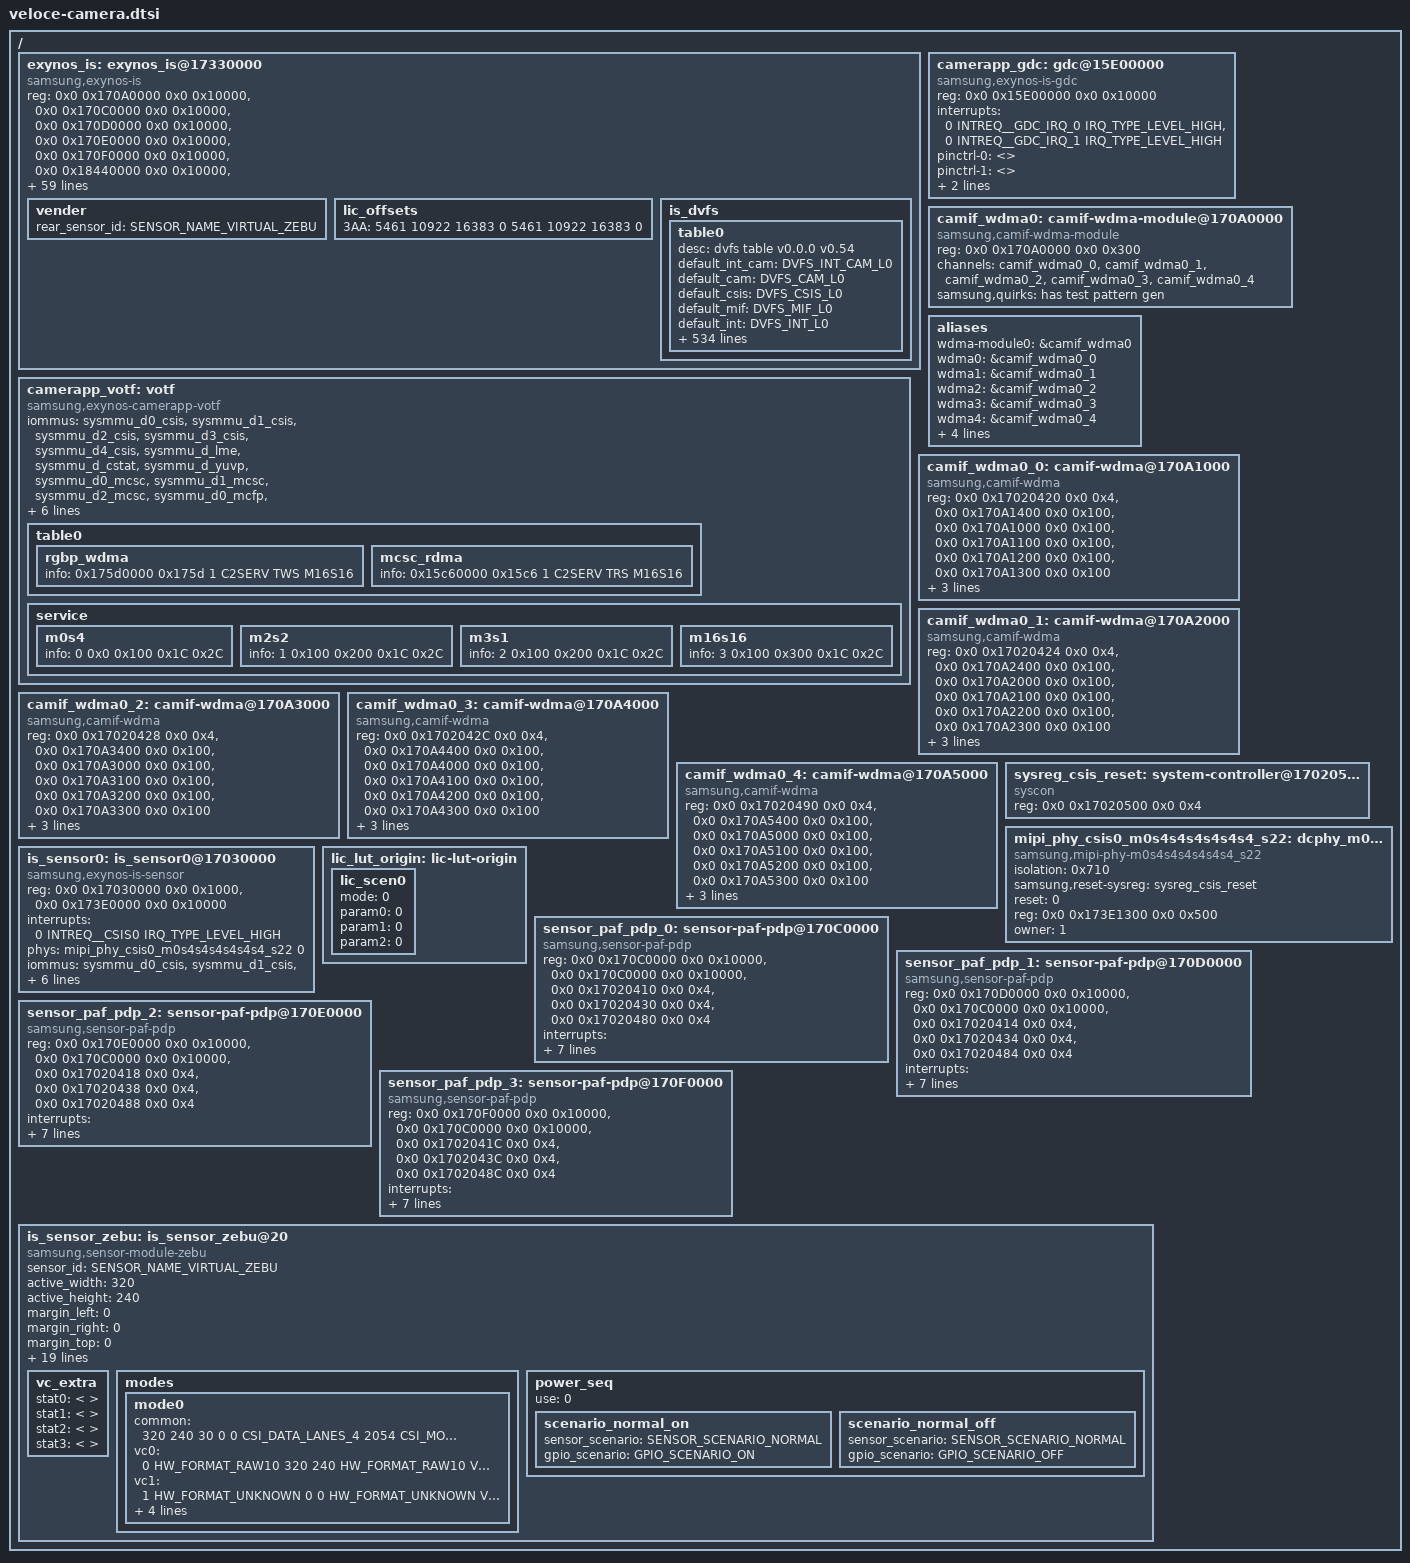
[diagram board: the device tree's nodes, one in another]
/*
 * SAMSUNG EXYNOS9925 SoC camera device tree source
 *
 * Copyright (c) 2020 Samsung Electronics Co., Ltd.
 *		http://www.samsung.com
 *
 * SAMSUNG EXYNOS9925 SoC camera device nodes are listed in this file.
 * EXYNOS9925 based board files can include this file and provide
 * values for board specfic bindings.
 *
 * This program is free software; you can redistribute it and/or modify
 * it under the terms of the GNU General Public License version 2 as
 * published by the Free Software Foundation.
 */

//#include <dt-bindings/clock/exynos9925.h>
#include <dt-bindings/interrupt-controller/arm-gic.h>
#include <dt-bindings/interrupt-controller/exynos9925.h>
#include <dt-bindings/soc/samsung,sysmmu-v8.h>
#include <dt-bindings/camera/exynos_is_dt.h>
#include <dt-bindings/camera/votf.h>
//#include "EXYNOS9925-pinctrl.dtsi"

/ {
	exynos_is: exynos_is@17330000 {
		compatible = "samsung,exynos-is";
		reg = <0x0 0x170A0000 0x0 0x10000>, /* CSIS_WDMA */
			<0x0 0x170C0000 0x0 0x10000>, /* PDP_CORE0 */
			<0x0 0x170D0000 0x0 0x10000>, /* PDP_CORE1 */
			<0x0 0x170E0000 0x0 0x10000>, /* PDP_CORE2 */
			<0x0 0x170F0000 0x0 0x10000>, /* PDP_CORE3 */
			<0x0 0x18440000 0x0 0x10000>, /* CSTAT0 */
			<0x0 0x18450000 0x0 0x20000>, /* CSTAT1 */
			<0x0 0x18460000 0x0 0x30000>, /* CSTAT2 */
			<0x0 0x18470000 0x0 0x40000>, /* CSTAT3 */
			<0x0 0x170A0000 0x0 0x10000>, /* ZSL/STRIP DMA  */
			<0x0 0x17730000 0x0 0x10000>, /* LME */
			<0x0 0x15F80000 0x0 0x10000>, /* BYRP */
			<0x0 0x175B0000 0x0 0x10000>, /* RGBP */
			<0x0 0x17430000 0x0 0x10000>, /* DRCP */
			<0x0 0x17B00000 0x0 0x10000>, /* MCFP */
			<0x0 0x18080000 0x0 0x10000>, /* YUVP */
			<0x0 0x15C40000 0x0 0x10000>; /* MCSC */
		interrupts = <0 INTREQ__CSTAT_CH0_0 IRQ_TYPE_LEVEL_HIGH>, /*CSTAT0_0 */
			<0 INTREQ__CSTAT_CH0_1 IRQ_TYPE_LEVEL_HIGH>,      /* CSTAT0_1 */
			<0 INTREQ__CSTAT_CH1_0 IRQ_TYPE_LEVEL_HIGH>,      /* CSTAT1_0 */
			<0 INTREQ__CSTAT_CH1_1 IRQ_TYPE_LEVEL_HIGH>,      /* CSTAT1_1 */
			<0 INTREQ__CSTAT_CH2_0 IRQ_TYPE_LEVEL_HIGH>,      /* CSTAT2_0 */
			<0 INTREQ__CSTAT_CH2_1 IRQ_TYPE_LEVEL_HIGH>,      /* CSTAT2_1 */
			<0 INTREQ__CSTAT_CH3_0 IRQ_TYPE_LEVEL_HIGH>,      /* CSTAT3_0 */
			<0 INTREQ__CSTAT_CH3_1 IRQ_TYPE_LEVEL_HIGH>,      /* CSTAT3_1 */
			<0 INTREQ__LME_O_INT0 IRQ_TYPE_LEVEL_HIGH>,       /* LME_0 */
			<0 INTREQ__BYRP_0 IRQ_TYPE_LEVEL_HIGH>,           /* BYRP_0 */
			<0 INTREQ__BYRP_1 IRQ_TYPE_LEVEL_HIGH>,           /* BYRP_1 */
			<0 INTREQ__RGBP_0 IRQ_TYPE_LEVEL_HIGH>,           /* RGBP_0 */
			<0 INTREQ__RGBP_1 IRQ_TYPE_LEVEL_HIGH>,           /* RGBP_1 */
			<0 INTREQ__MCFP_0 IRQ_TYPE_LEVEL_HIGH>,           /* MCFP_0 */
			<0 INTREQ__MCFP_1 IRQ_TYPE_LEVEL_HIGH>,           /* MCFP_1 */
			<0 INTREQ__YUVP_0 IRQ_TYPE_LEVEL_HIGH>,           /* YUVP_0 */
			<0 INTREQ__YUVP_1 IRQ_TYPE_LEVEL_HIGH>,           /* YUVP_1 */
			<0 INTREQ__DRCP_0 IRQ_TYPE_LEVEL_HIGH>,           /* DRCP_0 */
			<0 INTREQ__DRCP_1 IRQ_TYPE_LEVEL_HIGH>,           /* DRCP_1 */
			<0 INTREQ__MCSC_INTREQ_0 IRQ_TYPE_LEVEL_HIGH>,    /* MCSC_0 */
			<0 INTREQ__MCSC_INTREQ_1 IRQ_TYPE_LEVEL_HIGH>;    /* MCSC_1 */
		pinctrl-names = "default","release";
		pinctrl-0 = <>;
		pinctrl-1 = <>;

		status = "ok";
		iommus = <&sysmmu_d0_csis>,
			<&sysmmu_d1_csis>,
			<&sysmmu_d2_csis>,
			<&sysmmu_d3_csis>,
			<&sysmmu_d4_csis>,
			<&sysmmu_d_lme>,
			<&sysmmu_d_cstat>,
			<&sysmmu_d_yuvp>,
			<&sysmmu_d0_mcsc>,
			<&sysmmu_d1_mcsc>,
			<&sysmmu_d2_mcsc>,
			<&sysmmu_d0_mcfp>,
			<&sysmmu_d1_mcfp>,
			<&sysmmu_d2_mcfp>,
			<&sysmmu_d3_mcfp>,
			<&sysmmu_d4_mcfp>,
			<&sysmmu_d5_mcfp>,
			<&sysmmu_d0_rgbp>,
			<&sysmmu_d1_rgbp>,
			<&sysmmu_d_drcp>,
			<&sysmmu_d_byrp>;
		samsung,iommu-group = <&iommu_group_is>;
		#cooling-cells = <2>; /* min followed by max */
		/* ewf-index = <EWF_CMU_BUSC>; */
		list-scen-bts = "camera_default";
		num_of_3aa = <4>;
		num_of_lme = <1>;
		num_of_isp = <0>;
		num_of_byrp = <1>;
		num_of_rgbp = <1>;
		num_of_mcsc = <1>;
		num_of_vra = <0>;
		num_of_clh = <0>;
		num_of_ypp = <1>;
		num_of_mcfp = <1>;

		memory-region = <&camera_rmem>;
		samsung,tzmp;
	};

	camerapp_gdc: gdc@15E00000 {
		compatible = "samsung,exynos-is-gdc";
		reg = <0x0 0x15E00000 0x0 0x10000>; /* GDC */
		interrupts = <0 INTREQ__GDC_IRQ_0 IRQ_TYPE_LEVEL_HIGH>, /* GDC_0 */
			<0 INTREQ__GDC_IRQ_1 IRQ_TYPE_LEVEL_HIGH>;    /* GDC_1 */
		pinctrl-names = "default","release";
		pinctrl-0 = <>;
		pinctrl-1 = <>;

		status = "okay";
		iommus = <&sysmmu_d0_mcsc>;
		samsung,iommu-group = <&iommu_group_is>;
		#cooling-cells = <2>; /* min followed by max */
	};

	camerapp_votf: votf {
		compatible = "samsung,exynos-camerapp-votf";
		iommus = <&sysmmu_d0_csis>,
			<&sysmmu_d1_csis>,
			<&sysmmu_d2_csis>,
			<&sysmmu_d3_csis>,
			<&sysmmu_d4_csis>,
			<&sysmmu_d_lme>,
			<&sysmmu_d_cstat>,
			<&sysmmu_d_yuvp>,
			<&sysmmu_d0_mcsc>,
			<&sysmmu_d1_mcsc>,
			<&sysmmu_d2_mcsc>,
			<&sysmmu_d0_mcfp>,
			<&sysmmu_d1_mcfp>,
			<&sysmmu_d2_mcfp>,
			<&sysmmu_d3_mcfp>,
			<&sysmmu_d4_mcfp>,
			<&sysmmu_d5_mcfp>,
			<&sysmmu_d0_rgbp>,
			<&sysmmu_d1_rgbp>,
			<&sysmmu_d_drcp>,
			<&sysmmu_d_byrp>;
		samsung,iommu-group = <&iommu_group_is>;
		status = "okay";
		use_axi;

		table0{
			/* base address, ip num, id cnt, C2SERV/C2AGENT, TWS/TRS, module type */
			/*
			csis_wdma0 { info = <0x17380000 0x1738 16 C2SERV TWS M16S16>; };
			csis_wdma1 { info = <0x17390000 0x1739 4 C2SERV TWS M16S16>; };
			pdp_rdma   { info = <0x173a0000 0x173a 4 C2SERV TRS M16S16>; };
			byrp_wdma  { info = <0x15fa0000 0x15fa 2 C2SERV TWS M16S16>; };
			byrp_rdma  { info = <0x15fc0000 0x15fc 1 C2SERV TRS M16S16>; };
			cstat_wdma0 { info = <0x18510000 0x1851 16 C2SERV TWS M16S16>; };
			cstat_wdma1 { info = <0x18520000 0x1852 16 C2SERV TWS M16S16>; };
			cstat_wdma2 { info = <0x18530000 0x1853 4 C2SERV TWS M16S16>; };
			cstat_rdma { info = <0x18500000 0x1850 4 C2SERV TRS M16S16>; };
			rgbp_rdma { info = <0x175c0000 0x175c 4 C2SERV TWS M16S16>; };
			*/
			rgbp_wdma { info = <0x175d0000 0x175d 1 C2SERV TWS M16S16>; };
			mcsc_rdma  { info = <0x15c60000 0x15c6 1 C2SERV TRS M16S16>; };
			/*
			mcsc_wdma  { info = <0x16c50000 0x15c5 16 C2SERV TWS M16S16>; };
			gdc_rdma   { info = <0x15e20000 0x15e2 2 C2SERV TRS M16S16>; };
			gdc_wdma   { info = <0x15e10000 0x15e1 1 C2SERV TWS M16S16>; };
			lme_rdma   { info = <0x17740000 0x1774 16 C2SERV TRS M16S16>; };
			*/
		};

		service {
			/* num, tws addr, trs addr, tws gap, trs gap */
			m0s4 { info = <0 0x0 0x100 0x1C 0x2C>; };
			m2s2 { info = <1 0x100 0x200 0x1C 0x2C>; };
			m3s1 { info = <2 0x100 0x200 0x1C 0x2C>; };
			m16s16 { info = <3 0x100 0x300 0x1C 0x2C>; };
		};
	};

	camif_wdma0: camif-wdma-module@170A0000 {
		compatible = "samsung,camif-wdma-module";
		reg = <0x0 0x170A0000 0x0 0x300>;
		reg-names = "ctl";
		channels = <&camif_wdma0_0>,
			<&camif_wdma0_1>,
			<&camif_wdma0_2>,
			<&camif_wdma0_3>,
			<&camif_wdma0_4>;
		samsung,quirks = "has test pattern gen";
	};

	aliases {
		wdma-module0 = &camif_wdma0;
	};

	camif_wdma0_0: camif-wdma@170A1000 {
		compatible = "samsung,camif-wdma";
		reg = <0x0 0x17020420 0x0 0x4>,	/* input MUX */
			<0x0 0x170A1400 0x0 0x100>,	/* CTL */
			<0x0 0x170A1000 0x0 0x100>,	/* VC0 */
			<0x0 0x170A1100 0x0 0x100>,	/* VC1 */
			<0x0 0x170A1200 0x0 0x100>,	/* VC2 */
			<0x0 0x170A1300 0x0 0x100>;	/* VC3 */
		reg-names = "mux", "ctl", "vc0", "vc1", "vc2", "vc3";
		interrupts = <GIC_SPI INTREQ__CSIS_DMA0 IRQ_TYPE_LEVEL_HIGH>;
		interrupt-names = "dma";
		module = <&camif_wdma0>;
	};

	camif_wdma0_1: camif-wdma@170A2000 {
		compatible = "samsung,camif-wdma";
		reg = <0x0 0x17020424 0x0 0x4>,	/* input MUX */
			<0x0 0x170A2400 0x0 0x100>,	/* CTL */
			<0x0 0x170A2000 0x0 0x100>,	/* VC0 */
			<0x0 0x170A2100 0x0 0x100>,	/* VC1 */
			<0x0 0x170A2200 0x0 0x100>,	/* VC2 */
			<0x0 0x170A2300 0x0 0x100>;	/* VC3 */
		reg-names = "mux", "ctl", "vc0", "vc1", "vc2", "vc3";
		interrupts = <GIC_SPI INTREQ__CSIS_DMA1 IRQ_TYPE_LEVEL_HIGH>;
		interrupt-names = "dma";
		module = <&camif_wdma0>;
	};

	camif_wdma0_2: camif-wdma@170A3000 {
		compatible = "samsung,camif-wdma";
		reg = <0x0 0x17020428 0x0 0x4>,	/* input MUX */
			<0x0 0x170A3400 0x0 0x100>,	/* CTL */
			<0x0 0x170A3000 0x0 0x100>,	/* VC0 */
			<0x0 0x170A3100 0x0 0x100>,	/* VC1 */
			<0x0 0x170A3200 0x0 0x100>,	/* VC2 */
			<0x0 0x170A3300 0x0 0x100>;	/* VC3 */
		reg-names = "mux", "ctl", "vc0", "vc1", "vc2", "vc3";
		interrupts = <GIC_SPI INTREQ__CSIS_DMA2 IRQ_TYPE_LEVEL_HIGH>;
		interrupt-names = "dma";
		module = <&camif_wdma0>;
	};

	camif_wdma0_3: camif-wdma@170A4000 {
		compatible = "samsung,camif-wdma";
		reg = <0x0 0x1702042C 0x0 0x4>,	/* input MUX */
			<0x0 0x170A4400 0x0 0x100>,	/* CTL */
			<0x0 0x170A4000 0x0 0x100>,	/* VC0 */
			<0x0 0x170A4100 0x0 0x100>,	/* VC1 */
			<0x0 0x170A4200 0x0 0x100>,	/* VC2 */
			<0x0 0x170A4300 0x0 0x100>;	/* VC3 */
		reg-names = "mux", "ctl", "vc0", "vc1", "vc2", "vc3";
		interrupts = <GIC_SPI INTREQ__CSIS_DMA3 IRQ_TYPE_LEVEL_HIGH>;
		interrupt-names = "dma";
		module = <&camif_wdma0>;
	};

	camif_wdma0_4: camif-wdma@170A5000 {
		compatible = "samsung,camif-wdma";
		reg = <0x0 0x17020490 0x0 0x4>,	/* input MUX */
			<0x0 0x170A5400 0x0 0x100>,	/* CTL */
			<0x0 0x170A5000 0x0 0x100>,	/* VC0 */
			<0x0 0x170A5100 0x0 0x100>,	/* VC1 */
			<0x0 0x170A5200 0x0 0x100>,	/* VC2 */
			<0x0 0x170A5300 0x0 0x100>;	/* VC3 */
		reg-names = "mux", "ctl", "vc0", "vc1", "vc2", "vc3";
		interrupts = <GIC_SPI INTREQ__CSIS_DMA4 IRQ_TYPE_LEVEL_HIGH>;
		interrupt-names = "dma";
		module = <&camif_wdma0>;
	};

	aliases {
		wdma0 = &camif_wdma0_0;
		wdma1 = &camif_wdma0_1;
		wdma2 = &camif_wdma0_2;
		wdma3 = &camif_wdma0_3;
		wdma4 = &camif_wdma0_4;
	};

	sysreg_csis_reset: system-controller@17020500 {
		compatible = "syscon";
		reg = <0x0 0x17020500 0x0 0x4>;
	};

	mipi_phy_csis0_m0s4s4s4s4s4s4_s22: dcphy_m0s4s4s4s4s4s4_s22_csi0@173E1300 {
		/* DPHY 6.5Gbps 4-lane, CPHY 6.0 Gsps 3-trio */
		compatible = "samsung,mipi-phy-m0s4s4s4s4s4s4_s22";

		//samsung,pmu-syscon = <&pmu_system_controller>;
		isolation = <0x710>; /* PMU address offset */

		samsung,reset-sysreg = <&sysreg_csis_reset>;
		reset = <0>; /* reset bit */

		reg = <0x0 0x173E1300 0x0 0x500>;
		owner = <1>; /* 0: DSI, 1: CSI */
		#phy-cells = <1>;
	};

	is_sensor0: is_sensor0@17030000 {
		/* CSIS0 */
		compatible = "samsung,exynos-is-sensor";
		#address-cells = <1>;
		#size-cells = <1>;
		reg = <0x0 0x17030000 0x0 0x1000>, /* MIPI-CSI0 */
			<0x0 0x173E0000 0x0 0x10000>; /* PHY: M0S4S4S4S4S4S4_S22 */
		reg-names = "csi", "phy";
		interrupts = <0 INTREQ__CSIS0 IRQ_TYPE_LEVEL_HIGH>; /* MIPI-CSI0 */
		interrupt-names = "csi";
		phys = <&mipi_phy_csis0_m0s4s4s4s4s4s4_s22 0>;
		phy-names = "csis_dphy";
		iommus = <&sysmmu_d0_csis>,
		       <&sysmmu_d1_csis>,
		       <&sysmmu_d2_csis>,
		       <&sysmmu_d3_csis>,
		       <&sysmmu_d4_csis>;
		samsung,iommu-group = <&iommu_group_is>;
	};

	lic_lut_origin: lic-lut-origin {
		#define LIC_MODE_DYNAMIC	(0)
		#define LIC_MODE_STATIC		(1)
		#define LIC_PATH_OTF		(0)
		#define LIC_PATH_DMA		(1)
		/*
		 * When DYNAMIC mode is selected, param means enable limitation for DMA path.
		 * Example:
		 * @ mode = <LIC_MODE_DYNAMIC>;
		 * @ param0 = <LIC_PATH_OTF>;
		 * @ param1 = <LIC_PATH_DMA>;
		 * @ param2 = <LIC_PATH_OTF>;
		 *
		 * When STATIC mode is selected, param means buffer size for each context.
		 * Example:
		 * @ mode = <LIC_MODE_STAIC>;
		 * @ param0 = <3584>;
		 * @ param1 = <3583>;
		 * @ param2 = <1>;
		 *
		 * The lic_scen0 is not abailable. If the index of LUT is "0", the selection is skipped.
		 */
		lic_scen0 { /* Reserved */
			mode = <0>;
			param0 = <0>;
			param1 = <0>;
			param2 = <0>;
		};
	};

	sensor_paf_pdp_0: sensor-paf-pdp@170C0000 {
		compatible = "samsung,sensor-paf-pdp";
		reg = <0x0 0x170C0000 0x0 0x10000>, /* PDP CORE0 */
			<0x0 0x170C0000 0x0 0x10000>, /* PDP CORE0: For common regiser */
			<0x0 0x17020410 0x0 0x4>, /* CSIS_PDP_SC_CON0: PDP0 input mux */
			<0x0 0x17020430 0x0 0x4>, /* PDP_VC_CON0: PDP0 VC input mux */
			<0x0 0x17020480 0x0 0x4>; /* CSIS_PDP_SC_PDP0_IN_EN: PDP0 input enable */
		reg-names = "core", "common", "mux", "vc_mux", "en";
		interrupts = <0 INTREQ__PDP0 IRQ_TYPE_LEVEL_HIGH>,
			<0 INTREQ__PDP1 IRQ_TYPE_LEVEL_HIGH>;
		mux = <0 1 2 3 4 5>; /* <csi0 csi1 csi2 csi3 csi4 csi5> */
		vc_mux = <0x1 0x1 0x1 0x1 0x1 0x1 0x1>; /* <csi0 csi1 csi2 csi3 csi4 csi5 csi6> */
		en = <0 1 2 3 4 5 6>; /* bit postion: <csi0 csi1 csi2 csi3 csi4 csi5 csi6> */
		leader; /* have RDMA & create video node */
		lic_lut = <&lic_lut_origin>;
		//clocks = <&clock GATE_PDP_TOP_QCH_PDP_TOP>;
		//clock-names = "aclk";

	};

	sensor_paf_pdp_1: sensor-paf-pdp@170D0000 {
		compatible = "samsung,sensor-paf-pdp";
		reg = <0x0 0x170D0000 0x0 0x10000>, /* PDP CORE1 */
			<0x0 0x170C0000 0x0 0x10000>, /* PDP CORE0: For common regiser */
			<0x0 0x17020414 0x0 0x4>, /* CSIS_PDP_SC_CON1: PDP1 input mux */
			<0x0 0x17020434 0x0 0x4>, /* PDP_VC_CON1: PDP1 VC input mux */
			<0x0 0x17020484 0x0 0x4>; /* CSIS_PDP_SC_PDP1_IN_EN: PDP1 input enable */
		reg-names = "core", "common", "mux", "vc_mux", "en";
		interrupts = <0 INTREQ__PDP2 IRQ_TYPE_LEVEL_HIGH>,
			<0 INTREQ__PDP3 IRQ_TYPE_LEVEL_HIGH>;
		mux = <0 1 2 3 4 5>; /* <csi0 csi1 csi2 csi3 csi4 csi5> */
		vc_mux = <0x1 0x1 0x1 0x1 0x1 0x1 0x1>; /* <csi0 csi1 csi2 csi3 csi4 csi5 csi6> */
		en = <0 1 2 3 4 5 6>; /* bit postion: <csi0 csi1 csi2 csi3 csi4 csi5 csi6> */
		leader; /* have RDMA & create video node */
		lic_lut = <&lic_lut_origin>;
		//clocks = <&clock GATE_PDP_TOP_QCH_PDP_TOP>;
		//clock-names = "aclk";

	};

	sensor_paf_pdp_2: sensor-paf-pdp@170E0000 {
		compatible = "samsung,sensor-paf-pdp";
		reg = <0x0 0x170E0000 0x0 0x10000>, /* PDP CORE2 */
			<0x0 0x170C0000 0x0 0x10000>, /* PDP CORE0: For common regiser */
			<0x0 0x17020418 0x0 0x4>, /* CSIS_PDP_SC_CON2: PDP2 input mux */
			<0x0 0x17020438 0x0 0x4>, /* PDP_VC_CON2: PDP2 VC input mux */
			<0x0 0x17020488 0x0 0x4>; /* CSIS_PDP_SC_PDP2_IN_EN: PDP2 input enable */
		reg-names = "core", "common", "mux", "vc_mux", "en";
		interrupts = <0 INTREQ__PDP4 IRQ_TYPE_LEVEL_HIGH>,
			<0 INTREQ__PDP5 IRQ_TYPE_LEVEL_HIGH>;
		mux = <0 1 2 3 4 5>; /* <csi0 csi1 csi2 csi3 csi4 csi5> */
		vc_mux = <0x1 0x1 0x1 0x1 0x1 0x1 0x1>; /* <csi0 csi1 csi2 csi3 csi4 csi5 csi6> */
		en = <0 1 2 3 4 5 6>; /* bit postion: <csi0 csi1 csi2 csi3 csi4 csi5 csi6> */
		leader; /* have RDMA & create video node */
		lic_lut = <&lic_lut_origin>;
		//clocks = <&clock GATE_PDP_TOP_QCH_PDP_TOP>;
		//clock-names = "aclk";

	};

	sensor_paf_pdp_3: sensor-paf-pdp@170F0000 {
		compatible = "samsung,sensor-paf-pdp";
		reg = <0x0 0x170F0000 0x0 0x10000>, /* PDP CORE3 */
			<0x0 0x170C0000 0x0 0x10000>, /* PDP CORE0: For common regiser */
			<0x0 0x1702041C 0x0 0x4>, /* CSIS_PDP_SC_CON3: PDP3 input mux */
			<0x0 0x1702043C 0x0 0x4>, /* PDP_VC_CON3: PDP3 VC input mux */
			<0x0 0x1702048C 0x0 0x4>; /* CSIS_PDP_SC_PDP3_IN_EN: PDP3 input enable */
		reg-names = "core", "common", "mux", "vc_mux", "en";
		interrupts = <0 INTREQ__PDP6 IRQ_TYPE_LEVEL_HIGH>,
			<0 INTREQ__PDP7 IRQ_TYPE_LEVEL_HIGH>;
		mux = <0 1 2 3 4 5>; /* <csi0 csi1 csi2 csi3 csi4 csi5> */
		vc_mux = <0x1 0x1 0x1 0x1 0x1 0x1 0x1>; /* <csi0 csi1 csi2 csi3 csi4 csi5 csi6> */
		en = <0 1 2 3 4 5 6>; /* bit postion: <csi0 csi1 csi2 csi3 csi4 csi5 csi6> */
		leader; /* have RDMA & create video node */
		lic_lut = <&lic_lut_origin>;
		//clocks = <&clock GATE_PDP_TOP_QCH_PDP_TOP>;
		//clock-names = "aclk";

	};

	aliases {
		pdp0 = &sensor_paf_pdp_0;
		pdp1 = &sensor_paf_pdp_1;
		pdp2 = &sensor_paf_pdp_2;
		pdp3 = &sensor_paf_pdp_3;
	};

	is_sensor_zebu: is_sensor_zebu@20 {
		compatible = "samsung,sensor-module-zebu";
		/* common */
		sensor_id = <SENSOR_NAME_VIRTUAL_ZEBU>;
		active_width = <320>;
		active_height = <240>;
		margin_left = <0>;
		margin_right = <0>;
		margin_top = <0>;
		margin_bottom = <0>;
		max_framerate = <30>;
		bitwidth = <10>;
		use_retention_mode = <SENSOR_RETENTION_INACTIVE>;
		sensor_maker = "SLSI";
		sensor_name = "ZEBU";
		setfile_name = "setfile_rear.bin";

		pinctrl-names = "pin0", "pin1", "pin2", "release";
		pinctrl-0 = <>;
		pinctrl-1 = <>;
		pinctrl-2 = <>;
		pinctrl-3 = <>;

		use_img_drv = <1>;
		reg = <0x0 0x0FC00000 0x0 0x10000>; /* IMG_DRV */
		rmem = <&img_drv_rmem>;
		bin_path = "/data/";

		/* board */
		position = <0>;	/* Rear:0. Front:1. Rear_sub:2. Secure:3. */
		id = <0>; /* is_sensor id */
		mclk_ch = <0>;
		sensor_i2c_ch = <0>; /* SENSOR_CONTROL_I2C0 */

		status = "okay";

		vc_extra {
			/* ex) statX = <stat_type, sensor_mode, max_width, max_height, max_element> */
			stat0 = </* not avaliable */>;	/* VC_BUF_DATA_TYPE_SENSOR_STAT1 */
			stat1 = </* not available */>;	/* VC_BUF_DATA_TYPE_GENERAL_STAT1 */
			stat2 = </* not avaliable */>;	/* VC_BUF_DATA_TYPE_SENSOR_STAT2 */
			stat3 = </* not available */>;	/* VC_BUF_DATA_TYPE_GENERAL_STAT2 */
		};

		/* sensor modes */
		modes {
				/* common = <width, height, fps, settle, mode, lane, speed, interleave, lrte, pd_mode> */
				/* vcX = <map, hwformat, width, height, hwformat, type, width, height> */
			mode0 {
				common = <320 240 30 0 0 CSI_DATA_LANES_4 2054 CSI_MODE_VC_DT LRTE_DISABLE PD_NONE EX_NONE>;
				vc0 = </* in */ 0 HW_FORMAT_RAW10 320 240	/* out */ HW_FORMAT_RAW10 VC_NOTHING 320 240>;
				vc1 = </* in */ 1 HW_FORMAT_UNKNOWN 0 0		/* out */ HW_FORMAT_UNKNOWN VC_NOTHING 0 0>;
				vc2 = </* in */ 2 HW_FORMAT_UNKNOWN 0 0		/* out */ HW_FORMAT_UNKNOWN VC_NOTHING 0 0>;
				vc3 = </* in */ 3 HW_FORMAT_UNKNOWN 0 0		/* out */ HW_FORMAT_UNKNOWN VC_NOTHING 0 0>;
			};
		};

		power_seq {
			use = <0>;
			scenario_normal_on {
				sensor_scenario = <SENSOR_SCENARIO_NORMAL>;
				gpio_scenario = <GPIO_SCENARIO_ON>;

				/* A start node number should be over the 10 for reserved number 0~9. */
				/* pname = "name"; pin = <act value dealy voltage>; gpio = <gpx# # 0x1>; */
			};

			scenario_normal_off {
				sensor_scenario = <SENSOR_SCENARIO_NORMAL>;
				gpio_scenario = <GPIO_SCENARIO_OFF>;

				/* A start node number should be over the 10 for reserved number 0~9. */
				/* pname = "name"; pin = <act value dealy voltage>; gpio = <gpx# # 0x1>; */
			};
		};
	};
};

&is_sensor0 {
	#address-cells = <1>;
	#size-cells = <1>;
	scenario = <SENSOR_SCENARIO_NORMAL>; /* Normal, Vision, OIS etc */
	id = <0>;
	csi_ch = <0>;
	status = "okay";
};

&exynos_is {
	vender {
		rear_sensor_id = <SENSOR_NAME_VIRTUAL_ZEBU>;
	};

	lic_offsets {
		/* 3AA = <setA lic offset0, setA lic offset1, set A trigger context */
		/*		setB lic offset0, setB lic offset1, set B trigger context> */
		/* 4672: 4640x4352 */
		/* 5824: 5804x4352 */
		3AA = <5461 10922 16383 0 5461 10922 16383 0>;
	};

	is_dvfs {
		#define DVFS_INT_CAM_L0 690000
		#define DVFS_INT_CAM_L1 680000
		#define DVFS_INT_CAM_L2 670000
		#define DVFS_INT_CAM_L3 660000
		#define DVFS_INT_CAM_L4 650000
		#define DVFS_INT_CAM_L5 640000
		#define DVFS_INT_CAM_L6 630000
		#define DVFS_INT_CAM_L7 620000

		#define DVFS_INT_L0 800000
		#define DVFS_INT_L1 533000
		#define DVFS_INT_L2 400000
		#define DVFS_INT_L3 267000
		#define DVFS_INT_L4 80000

		#define DVFS_CSIS_L0 690000
		#define DVFS_CSIS_L1 680000
		#define DVFS_CSIS_L2 670000
		#define DVFS_CSIS_L3 660000
		#define DVFS_CSIS_L4 650000
		#define DVFS_CSIS_L5 640000

		#define DVFS_CAM_L0 690000
		#define DVFS_CAM_L1 680000
		#define DVFS_CAM_L2 670000
		#define DVFS_CAM_L3 660000
		#define DVFS_CAM_L4 650000
		#define DVFS_CAM_L5 640000

		#define DVFS_MIF_L0 3172000
		#define DVFS_MIF_L1 2730000
		#define DVFS_MIF_L2 2535000
		#define DVFS_MIF_L3 2288000
		#define DVFS_MIF_L4 2028000
		#define DVFS_MIF_L5 1716000
		#define DVFS_MIF_L6 1539000
		#define DVFS_MIF_L7 1352000
		#define DVFS_MIF_L8 1014000
		#define DVFS_MIF_L9 845000
		#define DVFS_MIF_L10 546000
		#define DVFS_MIF_L11 421000

		table0 {
			desc = "dvfs table v0.0.0 v0.54";

			default_int_cam = <DVFS_INT_CAM_L0>;
			default_cam = <DVFS_CAM_L0>;
			default_csis = <DVFS_CSIS_L0>;
			default_mif = <DVFS_MIF_L0>;
			default_int = <DVFS_INT_L0>;
			default_hpg = <1>;

			front2_preview_int_cam = <DVFS_INT_CAM_L5>;
			front2_preview_cam = <DVFS_CAM_L3>;
			front2_preview_csis = <DVFS_CSIS_L3>;
			front2_preview_mif = <DVFS_MIF_L6>;
			front2_preview_int = <DVFS_INT_L3>;
			front2_preview_hpg = <1>;

			front2_capture_int_cam = <DVFS_INT_CAM_L3>;
			front2_capture_cam = <DVFS_CAM_L3>;
			front2_capture_csis = <DVFS_CSIS_L3>;
			front2_capture_mif = <DVFS_MIF_L1>;
			front2_capture_int = <DVFS_INT_L0>;
			front2_capture_hpg = <1>;

			front2_video_int_cam = <DVFS_INT_CAM_L5>;
			front2_video_cam = <DVFS_CAM_L5>;
			front2_video_csis = <DVFS_CSIS_L5>;
			front2_video_mif = <DVFS_MIF_L6>;
			front2_video_int = <DVFS_INT_L3>;
			front2_video_hpg = <1>;

			front2_video_capture_int_cam = <DVFS_INT_CAM_L3>;
			front2_video_capture_cam = <DVFS_CAM_L3>;
			front2_video_capture_csis = <DVFS_CSIS_L3>;
			front2_video_capture_mif = <DVFS_MIF_L1>;
			front2_video_capture_int = <DVFS_INT_L0>;
			front2_video_capture_hpg = <1>;

			front_preview_int_cam = <DVFS_INT_CAM_L5>;
			front_preview_cam = <DVFS_CAM_L2>;
			front_preview_csis = <DVFS_CSIS_L2>;
			front_preview_mif = <DVFS_MIF_L6>;
			front_preview_int = <DVFS_INT_L3>;
			front_preview_hpg = <1>;

			front_preview_full_int_cam = <DVFS_INT_CAM_L5>;
			front_preview_full_cam = <DVFS_CAM_L2>;
			front_preview_full_csis = <DVFS_CSIS_L2>;
			front_preview_full_mif = <DVFS_MIF_L6>;
			front_preview_full_int = <DVFS_INT_L3>;
			front_preview_full_hpg = <1>;

			front_capture_int_cam = <DVFS_INT_CAM_L3>;
			front_capture_cam = <DVFS_CAM_L2>;
			front_capture_csis = <DVFS_CSIS_L2>;
			front_capture_mif = <DVFS_MIF_L1>;
			front_capture_int = <DVFS_INT_L0>;
			front_capture_hpg = <1>;

			front_video_int_cam = <DVFS_INT_CAM_L5>;
			front_video_cam = <DVFS_CAM_L2>;
			front_video_csis = <DVFS_CSIS_L2>;
			front_video_mif = <DVFS_MIF_L6>;
			front_video_int = <DVFS_INT_L3>;
			front_video_hpg = <1>;

			front_video_whd_int_cam = <DVFS_INT_CAM_L5>;
			front_video_whd_cam = <DVFS_CAM_L2>;
			front_video_whd_csis = <DVFS_CSIS_L2>;
			front_video_whd_mif = <DVFS_MIF_L6>;
			front_video_whd_int = <DVFS_INT_L3>;
			front_video_whd_hpg = <1>;

			front_video_uhd_int_cam = <DVFS_INT_CAM_L5>;
			front_video_uhd_cam = <DVFS_CAM_L2>;
			front_video_uhd_csis = <DVFS_CSIS_L2>;
			front_video_uhd_mif = <DVFS_MIF_L6>;
			front_video_uhd_int = <DVFS_INT_L3>;
			front_video_uhd_hpg = <1>;

			front_video_fhd_60fps_int_cam = <DVFS_INT_CAM_L5>;
			front_video_fhd_60fps_cam = <DVFS_CAM_L2>;
			front_video_fhd_60fps_csis = <DVFS_CSIS_L2>;
			front_video_fhd_60fps_mif = <DVFS_MIF_L6>;
			front_video_fhd_60fps_int = <DVFS_INT_L3>;
			front_video_fhd_60fps_hpg = <1>;

			front_video_uhd_60fps_int_cam = <DVFS_INT_CAM_L5>;
			front_video_uhd_60fps_cam = <DVFS_CAM_L2>;
			front_video_uhd_60fps_csis = <DVFS_CSIS_L2>;
			front_video_uhd_60fps_mif = <DVFS_MIF_L4>;
			front_video_uhd_60fps_int = <DVFS_INT_L3>;
			front_video_uhd_60fps_hpg = <1>;

			front_video_capture_int_cam = <DVFS_INT_CAM_L3>;
			front_video_capture_cam = <DVFS_CAM_L2>;
			front_video_capture_csis = <DVFS_CSIS_L2>;
			front_video_capture_mif = <DVFS_MIF_L1>;
			front_video_capture_int = <DVFS_INT_L0>;
			front_video_capture_hpg = <1>;

			front_video_whd_capture_int_cam = <DVFS_INT_CAM_L3>;
			front_video_whd_capture_cam = <DVFS_CAM_L2>;
			front_video_whd_capture_csis = <DVFS_CSIS_L2>;
			front_video_whd_capture_mif = <DVFS_MIF_L1>;
			front_video_whd_capture_int = <DVFS_INT_L0>;
			front_video_whd_capture_hpg = <1>;

			front_video_uhd_capture_int_cam = <DVFS_INT_CAM_L3>;
			front_video_uhd_capture_cam = <DVFS_CAM_L2>;
			front_video_uhd_capture_csis = <DVFS_CSIS_L2>;
			front_video_uhd_capture_mif = <DVFS_MIF_L1>;
			front_video_uhd_capture_int = <DVFS_INT_L0>;
			front_video_uhd_capture_hpg = <1>;

			front_video_uhd_60fps_capture_int_cam = <DVFS_INT_CAM_L3>;
			front_video_uhd_60fps_capture_cam = <DVFS_CAM_L2>;
			front_video_uhd_60fps_capture_csis = <DVFS_CSIS_L2>;
			front_video_uhd_60fps_capture_mif = <DVFS_MIF_L1>;
			front_video_uhd_60fps_capture_int = <DVFS_INT_L0>;
			front_video_uhd_60fps_capture_hpg = <1>;

			front_video_fhd_60fps_capture_int_cam = <DVFS_INT_CAM_L3>;
			front_video_fhd_60fps_capture_cam = <DVFS_CAM_L2>;
			front_video_fhd_60fps_capture_csis = <DVFS_CSIS_L2>;
			front_video_fhd_60fps_capture_mif = <DVFS_MIF_L1>;
			front_video_fhd_60fps_capture_int = <DVFS_INT_L0>;
			front_video_fhd_60fps_capture_hpg = <1>;

			front_dual_sync_preview_int_cam = <DVFS_INT_CAM_L5>;
			front_dual_sync_preview_cam = <DVFS_CAM_L3>;
			front_dual_sync_preview_csis = <DVFS_CSIS_L3>;
			front_dual_sync_preview_mif = <DVFS_MIF_L6>;
			front_dual_sync_preview_int = <DVFS_INT_L3>;
			front_dual_sync_preview_hpg = <1>;

			front_dual_sync_capture_int_cam = <DVFS_INT_CAM_L3>;
			front_dual_sync_capture_cam = <DVFS_CAM_L3>;
			front_dual_sync_capture_csis = <DVFS_CSIS_L3>;
			front_dual_sync_capture_mif = <DVFS_MIF_L1>;
			front_dual_sync_capture_int = <DVFS_INT_L0>;
			front_dual_sync_capture_hpg = <1>;

			front_dual_sync_video_fhd_int_cam = <DVFS_INT_CAM_L5>;
			front_dual_sync_video_fhd_cam = <DVFS_CAM_L3>;
			front_dual_sync_video_fhd_csis = <DVFS_CSIS_L3>;
			front_dual_sync_video_fhd_mif = <DVFS_MIF_L6>;
			front_dual_sync_video_fhd_int = <DVFS_INT_L3>;
			front_dual_sync_video_fhd_hpg = <1>;

			front_dual_sync_video_fhd_capture_int_cam = <DVFS_INT_CAM_L3>;
			front_dual_sync_video_fhd_capture_cam = <DVFS_CAM_L3>;
			front_dual_sync_video_fhd_capture_csis = <DVFS_CSIS_L3>;
			front_dual_sync_video_fhd_capture_mif = <DVFS_MIF_L1>;
			front_dual_sync_video_fhd_capture_int = <DVFS_INT_L0>;
			front_dual_sync_video_fhd_capture_hpg = <1>;

			front_vt1_int_cam = <DVFS_INT_CAM_L5>;
			front_vt1_cam = <DVFS_CAM_L5>;
			front_vt1_csis = <DVFS_CSIS_L5>;
			front_vt1_mif = <DVFS_MIF_L6>;
			front_vt1_int = <DVFS_INT_L3>;
			front_vt1_hpg = <1>;

			front_vt2_int_cam = <DVFS_INT_CAM_L5>;
			front_vt2_cam = <DVFS_CAM_L5>;
			front_vt2_csis = <DVFS_CSIS_L5>;
			front_vt2_mif = <DVFS_MIF_L6>;
			front_vt2_int = <DVFS_INT_L3>;
			front_vt2_hpg = <1>;

			front_vt4_int_cam = <DVFS_INT_CAM_L5>;
			front_vt4_cam = <DVFS_CAM_L5>;
			front_vt4_csis = <DVFS_CSIS_L5>;
			front_vt4_mif = <DVFS_MIF_L6>;
			front_vt4_int = <DVFS_INT_L3>;
			front_vt4_hpg = <1>;

			front_preview_high_speed_fps_int_cam = <DVFS_INT_CAM_L5>;
			front_preview_high_speed_fps_cam = <DVFS_CAM_L3>;
			front_preview_high_speed_fps_csis = <DVFS_CSIS_L3>;
			front_preview_high_speed_fps_mif = <DVFS_MIF_L4>;
			front_preview_high_speed_fps_int = <DVFS_INT_L3>;
			front_preview_high_speed_fps_hpg = <1>;

			rear3_preview_fhd_int_cam = <DVFS_INT_CAM_L5>;
			rear3_preview_fhd_cam = <DVFS_CAM_L1>;	/* OTF */
			rear3_preview_fhd_csis = <DVFS_CSIS_L1>;	/* OTF */
			rear3_preview_fhd_mif = <DVFS_MIF_L6>;
			rear3_preview_fhd_int = <DVFS_INT_L3>;
			rear3_preview_fhd_hpg = <1>;

			rear3_capture_int_cam = <DVFS_INT_CAM_L3>;
			rear3_capture_cam = <DVFS_CAM_L1>;		/* OTF */
			rear3_capture_csis = <DVFS_CSIS_L1>;		/* OTF */
			rear3_capture_mif = <DVFS_MIF_L1>;
			rear3_capture_int = <DVFS_INT_L3>;
			rear3_capture_hpg = <1>;

			rear3_video_fhd_int_cam = <DVFS_INT_CAM_L5>;
			rear3_video_fhd_cam = <DVFS_CAM_L1>;	/* OTF */
			rear3_video_fhd_csis = <DVFS_CSIS_L1>;	/* OTF */
			rear3_video_fhd_mif = <DVFS_MIF_L6>;
			rear3_video_fhd_int = <DVFS_INT_L3>;
			rear3_video_fhd_hpg = <1>;

			rear3_video_fhd_capture_int_cam = <DVFS_INT_CAM_L3>;
			rear3_video_fhd_capture_cam = <DVFS_CAM_L1>;	/* OTF */
			rear3_video_fhd_capture_csis = <DVFS_CSIS_L1>;	/* OTF */
			rear3_video_fhd_capture_mif = <DVFS_MIF_L1>;
			rear3_video_fhd_capture_int = <DVFS_INT_L3>;
			rear3_video_fhd_capture_hpg = <1>;

			rear2_preview_fhd_int_cam = <DVFS_INT_CAM_L5>;
			rear2_preview_fhd_cam = <DVFS_CAM_L1>;	/* VOTF */
			rear2_preview_fhd_csis = <DVFS_CSIS_L1>;	/* VOTF */
			rear2_preview_fhd_mif = <DVFS_MIF_L6>;
			rear2_preview_fhd_int = <DVFS_INT_L3>;
			rear2_preview_fhd_hpg = <1>;

			rear2_capture_int_cam = <DVFS_INT_CAM_L3>;
			rear2_capture_cam = <DVFS_CAM_L1>;	/* VOTF */
			rear2_capture_csis = <DVFS_CSIS_L1>;	/* VOTF */
			rear2_capture_mif = <DVFS_MIF_L1>;
			rear2_capture_int = <DVFS_INT_L0>;
			rear2_capture_hpg = <1>;

			rear2_video_fhd_int_cam = <DVFS_INT_CAM_L5>;
			rear2_video_fhd_cam = <DVFS_CAM_L1>;	/* VOTF */
			rear2_video_fhd_csis = <DVFS_CSIS_L1>;	/* VOTF */
			rear2_video_fhd_mif = <DVFS_MIF_L6>;
			rear2_video_fhd_int = <DVFS_INT_L3>;
			rear2_video_fhd_hpg = <1>;

			rear2_video_uhd_8k_int_cam = <DVFS_INT_CAM_L3>;
			rear2_video_uhd_8k_cam = <DVFS_CAM_L1>;	/* OTF */
			rear2_video_uhd_8k_csis = <DVFS_CSIS_L1>;	/* OTF */
			rear2_video_uhd_8k_mif = <DVFS_MIF_L1>;
			rear2_video_uhd_8k_int = <DVFS_INT_L1>;
			rear2_video_uhd_8k_hpg = <1>;

			rear2_video_fhd_capture_int_cam = <DVFS_INT_CAM_L3>;
			rear2_video_fhd_capture_cam = <DVFS_CAM_L1>;	/* VOTF */
			rear2_video_fhd_capture_csis = <DVFS_CSIS_L1>;	/* VOTF */
			rear2_video_fhd_capture_mif = <DVFS_MIF_L1>;
			rear2_video_fhd_capture_int = <DVFS_INT_L0>;
			rear2_video_fhd_capture_hpg = <1>;

			rear2_video_uhd_8k_capture_int_cam = <DVFS_INT_CAM_L1>;
			rear2_video_uhd_8k_capture_cam = <DVFS_CAM_L1>;	/* OTF */
			rear2_video_uhd_8k_capture_csis = <DVFS_CSIS_L1>;	/* OTF */
			rear2_video_uhd_8k_capture_mif = <DVFS_MIF_L1>;
			rear2_video_uhd_8k_capture_int = <DVFS_INT_L0>;
			rear2_video_uhd_8k_capture_hpg = <1>;

			rear_preview_fhd_int_cam = <DVFS_INT_CAM_L5>;
			rear_preview_fhd_cam = <DVFS_CAM_L3>;	/* VOTF */
			rear_preview_fhd_csis = <DVFS_CSIS_L3>;	/* VOTF */
			rear_preview_fhd_mif = <DVFS_MIF_L6>;
			rear_preview_fhd_int = <DVFS_INT_L3>;
			rear_preview_fhd_hpg = <1>;

			rear_preview_whd_int_cam = <DVFS_INT_CAM_L5>;
			rear_preview_whd_cam = <DVFS_CAM_L3>;	/* VOTF */
			rear_preview_whd_csis = <DVFS_CSIS_L3>;	/* VOTF */
			rear_preview_whd_mif = <DVFS_MIF_L6>;
			rear_preview_whd_int = <DVFS_INT_L3>;
			rear_preview_whd_hpg = <1>;

			rear_preview_uhd_int_cam = <DVFS_INT_CAM_L5>;
			rear_preview_uhd_cam = <DVFS_CAM_L3>;	/* VOTF */
			rear_preview_uhd_csis = <DVFS_CSIS_L3>;	/* VOTF */
			rear_preview_uhd_mif = <DVFS_MIF_L6>;
			rear_preview_uhd_int = <DVFS_INT_L3>;
			rear_preview_uhd_hpg = <1>;

			rear_preview_uhd_60fps_int_cam = <DVFS_INT_CAM_L5>;
			rear_preview_uhd_60fps_cam = <DVFS_CAM_L3>;	/* VOTF */
			rear_preview_uhd_60fps_csis = <DVFS_CSIS_L3>;	/* VOTF */
			rear_preview_uhd_60fps_mif = <DVFS_MIF_L6>;
			rear_preview_uhd_60fps_int = <DVFS_INT_L3>;
			rear_preview_uhd_60fps_hpg = <1>;

			rear_preview_full_int_cam = <DVFS_INT_CAM_L5>;
			rear_preview_full_cam = <DVFS_CAM_L3>;	/* VOTF */
			rear_preview_full_csis = <DVFS_CSIS_L3>;	/* VOTF */
			rear_preview_full_mif = <DVFS_MIF_L6>;
			rear_preview_full_int = <DVFS_INT_L3>;
			rear_preview_full_hpg = <1>;

			rear_capture_int_cam = <DVFS_INT_CAM_L3>;
			rear_capture_cam = <DVFS_CAM_L1>;	/* VOTF */
			rear_capture_csis = <DVFS_CSIS_L1>;	/* VOTF */
			rear_capture_mif = <DVFS_MIF_L1>;
			rear_capture_int = <DVFS_INT_L0>;
			rear_capture_hpg = <1>;

			rear_video_fhd_int_cam = <DVFS_INT_CAM_L5>;
			rear_video_fhd_cam = <DVFS_CAM_L4>;	/* VOTF */
			rear_video_fhd_csis = <DVFS_CSIS_L4>;	/* VOTF */
			rear_video_fhd_mif = <DVFS_MIF_L8>;
			rear_video_fhd_int = <DVFS_INT_L3>;
			rear_video_fhd_hpg = <1>;

			rear_video_hdr_int_cam = <DVFS_INT_CAM_L5>;
			rear_video_hdr_cam = <DVFS_CAM_L4>;	/* VOTF */
			rear_video_hdr_csis = <DVFS_CSIS_L4>;	/* VOTF */
			rear_video_hdr_mif = <DVFS_MIF_L6>;
			rear_video_hdr_int = <DVFS_INT_L3>;
			rear_video_hdr_hpg = <1>;

			rear_video_whd_int_cam = <DVFS_INT_CAM_L5>;
			rear_video_whd_cam = <DVFS_CAM_L4>;	/* VOTF */
			rear_video_whd_csis = <DVFS_CSIS_L4>;	/* VOTF */
			rear_video_whd_mif = <DVFS_MIF_L6>;
			rear_video_whd_int = <DVFS_INT_L3>;
			rear_video_whd_hpg = <1>;

			rear_video_uhd_int_cam = <DVFS_INT_CAM_L5>;
			rear_video_uhd_cam = <DVFS_CAM_L4>;	/* VOTF */
			rear_video_uhd_csis = <DVFS_CSIS_L4>;	/* VOTF */
			rear_video_uhd_mif = <DVFS_MIF_L6>;
			rear_video_uhd_int = <DVFS_INT_L3>;
			rear_video_uhd_hpg = <1>;

			rear_video_uhd_60fps_int_cam = <DVFS_INT_CAM_L5>;
			rear_video_uhd_60fps_cam = <DVFS_CAM_L4>;	/* VOTF */
			rear_video_uhd_60fps_csis = <DVFS_CSIS_L4>;	/* VOTF */
			rear_video_uhd_60fps_mif = <DVFS_MIF_L4>;
			rear_video_uhd_60fps_int = <DVFS_INT_L3>;
			rear_video_uhd_60fps_hpg = <1>;

			rear_video_uhd_8k_int_cam = <DVFS_INT_CAM_L4>;
			rear_video_uhd_8k_cam = <DVFS_CAM_L3>;	/* OTF */
			rear_video_uhd_8k_csis = <DVFS_CSIS_L3>;	/* OTF */
			rear_video_uhd_8k_mif = <DVFS_MIF_L1>;
			rear_video_uhd_8k_int = <DVFS_INT_L1>;
			rear_video_uhd_8k_hpg = <1>;

			rear_video_fhd_capture_int_cam = <DVFS_INT_CAM_L3>;
			rear_video_fhd_capture_cam = <DVFS_CAM_L3>;	/* VOTF */
			rear_video_fhd_capture_csis = <DVFS_CSIS_L3>;	/* VOTF */
			rear_video_fhd_capture_mif = <DVFS_MIF_L1>;
			rear_video_fhd_capture_int = <DVFS_INT_L0>;
			rear_video_fhd_capture_hpg = <1>;

			rear_video_hdr_capture_int_cam = <DVFS_INT_CAM_L3>;
			rear_video_hdr_capture_cam = <DVFS_CAM_L3>;	/* VOTF */
			rear_video_hdr_capture_csis = <DVFS_CSIS_L3>;	/* VOTF */
			rear_video_hdr_capture_mif = <DVFS_MIF_L1>;
			rear_video_hdr_capture_int = <DVFS_INT_L0>;
			rear_video_hdr_capture_hpg = <1>;

			rear_video_whd_capture_int_cam = <DVFS_INT_CAM_L3>;
			rear_video_whd_capture_cam = <DVFS_CAM_L3>;	/* VOTF */
			rear_video_whd_capture_csis = <DVFS_CSIS_L3>;	/* VOTF */
			rear_video_whd_capture_mif = <DVFS_MIF_L1>;
			rear_video_whd_capture_int = <DVFS_INT_L0>;
			rear_video_whd_capture_hpg = <1>;

			rear_video_uhd_capture_int_cam = <DVFS_INT_CAM_L3>;
			rear_video_uhd_capture_cam = <DVFS_CAM_L3>;	/* VOTF */
			rear_video_uhd_capture_csis = <DVFS_CSIS_L3>;	/* VOTF */
			rear_video_uhd_capture_mif = <DVFS_MIF_L1>;
			rear_video_uhd_capture_int = <DVFS_INT_L0>;
			rear_video_uhd_capture_hpg = <1>;

			rear_video_uhd_8k_capture_int_cam = <DVFS_INT_CAM_L3>;
			rear_video_uhd_8k_capture_cam = <DVFS_CAM_L3>;	/* VOTF */
			rear_video_uhd_8k_capture_csis = <DVFS_CSIS_L3>;	/* VOTF */
			rear_video_uhd_8k_capture_mif = <DVFS_MIF_L1>;
			rear_video_uhd_8k_capture_int = <DVFS_INT_L0>;
			rear_video_uhd_8k_capture_hpg = <1>;

			dual_preview_int_cam = <DVFS_INT_CAM_L3>;
			dual_preview_cam = <DVFS_CAM_L1>;	/* VOTF */
			dual_preview_csis = <DVFS_CSIS_L1>;	/* VOTF */
			dual_preview_mif = <DVFS_MIF_L1>;
			dual_preview_int = <DVFS_INT_L3>;
			dual_preview_hpg = <1>;

			dual_capture_int_cam = <DVFS_INT_CAM_L3>;
			dual_capture_cam = <DVFS_CAM_L1>;	/* VOTF */
			dual_capture_csis = <DVFS_CSIS_L1>;	/* VOTF */
			dual_capture_mif = <DVFS_MIF_L1>;
			dual_capture_int = <DVFS_INT_L0>;
			dual_capture_hpg = <1>;

			dual_video_fhd_int_cam = <DVFS_INT_CAM_L4>;
			dual_video_fhd_cam = <DVFS_CAM_L1>;	/* VOTF */
			dual_video_fhd_csis = <DVFS_CSIS_L1>;	/* VOTF */
			dual_video_fhd_mif = <DVFS_MIF_L6>;
			dual_video_fhd_int = <DVFS_INT_L3>;
			dual_video_fhd_hpg = <1>;

			dual_video_fhd_capture_int_cam = <DVFS_INT_CAM_L3>;
			dual_video_fhd_capture_cam = <DVFS_CAM_L1>;	/* VOTF */
			dual_video_fhd_capture_csis = <DVFS_CSIS_L1>;	/* VOTF */
			dual_video_fhd_capture_mif = <DVFS_MIF_L1>;
			dual_video_fhd_capture_int = <DVFS_INT_L0>;
			dual_video_fhd_capture_hpg = <1>;

			dual_video_uhd_int_cam = <DVFS_INT_CAM_L4>;
			dual_video_uhd_cam = <DVFS_CAM_L1>;	/* VOTF */
			dual_video_uhd_csis = <DVFS_CSIS_L1>;	/* VOTF */
			dual_video_uhd_mif = <DVFS_MIF_L6>;
			dual_video_uhd_int = <DVFS_INT_L3>;
			dual_video_uhd_hpg = <1>;

			dual_video_uhd_capture_int_cam = <DVFS_INT_CAM_L3>;
			dual_video_uhd_capture_cam = <DVFS_CAM_L1>;	/* VOTF */
			dual_video_uhd_capture_csis = <DVFS_CSIS_L1>;	/* VOTF */
			dual_video_uhd_capture_mif = <DVFS_MIF_L1>;
			dual_video_uhd_capture_int = <DVFS_INT_L0>;
			dual_video_uhd_capture_hpg = <1>;

			dual_sync_preview_int_cam = <DVFS_INT_CAM_L3>;
			dual_sync_preview_cam = <DVFS_CAM_L1>;	/* VOTF */
			dual_sync_preview_csis = <DVFS_CSIS_L1>;	/* VOTF */
			dual_sync_preview_mif = <DVFS_MIF_L1>;
			dual_sync_preview_int = <DVFS_INT_L3>;
			dual_sync_preview_hpg = <1>;

			dual_sync_capture_int_cam = <DVFS_INT_CAM_L3>;
			dual_sync_capture_cam = <DVFS_CAM_L1>;	/* VOTF */
			dual_sync_capture_csis = <DVFS_CSIS_L1>;	/* VOTF */
			dual_sync_capture_mif = <DVFS_MIF_L1>;
			dual_sync_capture_int = <DVFS_INT_L0>;
			dual_sync_capture_hpg = <1>;

			dual_sync_preview_whd_int_cam = <DVFS_INT_CAM_L3>;
			dual_sync_preview_whd_cam = <DVFS_CAM_L1>;	/* VOTF */
			dual_sync_preview_whd_csis = <DVFS_CSIS_L1>;	/* VOTF */
			dual_sync_preview_whd_mif = <DVFS_MIF_L1>;
			dual_sync_preview_whd_int = <DVFS_INT_L3>;
			dual_sync_preview_whd_hpg = <1>;

			dual_sync_whd_capture_int_cam = <DVFS_INT_CAM_L3>;
			dual_sync_whd_capture_cam = <DVFS_CAM_L1>;	/* VOTF */
			dual_sync_whd_capture_csis = <DVFS_CSIS_L1>;	/* VOTF */
			dual_sync_whd_capture_mif = <DVFS_MIF_L1>;
			dual_sync_whd_capture_int = <DVFS_INT_L0>;
			dual_sync_whd_capture_hpg = <1>;

			dual_sync_video_fhd_int_cam = <DVFS_INT_CAM_L4>;
			dual_sync_video_fhd_cam = <DVFS_CAM_L1>;	/* VOTF */
			dual_sync_video_fhd_csis = <DVFS_CSIS_L1>;	/* VOTF */
			dual_sync_video_fhd_mif = <DVFS_MIF_L6>;
			dual_sync_video_fhd_int = <DVFS_INT_L3>;
			dual_sync_video_fhd_hpg = <1>;

			dual_sync_video_fhd_capture_int_cam = <DVFS_INT_CAM_L3>;
			dual_sync_video_fhd_capture_cam = <DVFS_CAM_L1>;	/* VOTF */
			dual_sync_video_fhd_capture_csis = <DVFS_CSIS_L1>;	/* VOTF */
			dual_sync_video_fhd_capture_mif = <DVFS_MIF_L1>;
			dual_sync_video_fhd_capture_int = <DVFS_INT_L0>;
			dual_sync_video_fhd_capture_hpg = <1>;

			dual_sync_video_uhd_int_cam = <DVFS_INT_CAM_L4>;
			dual_sync_video_uhd_cam = <DVFS_CAM_L1>;	/* VOTF */
			dual_sync_video_uhd_csis = <DVFS_CSIS_L1>;	/* VOTF */
			dual_sync_video_uhd_mif = <DVFS_MIF_L6>;
			dual_sync_video_uhd_int = <DVFS_INT_L3>;
			dual_sync_video_uhd_hpg = <1>;

			dual_sync_video_uhd_capture_int_cam = <DVFS_INT_CAM_L3>;
			dual_sync_video_uhd_capture_cam = <DVFS_CAM_L1>;	/* VOTF */
			dual_sync_video_uhd_capture_csis = <DVFS_CSIS_L1>;	/* OTF */
			dual_sync_video_uhd_capture_mif = <DVFS_MIF_L1>;
			dual_sync_video_uhd_capture_int = <DVFS_INT_L0>;
			dual_sync_video_uhd_capture_hpg = <1>;

			secure_front_int_cam = <DVFS_INT_CAM_L5>;
			secure_front_cam = <DVFS_CAM_L5>;
			secure_front_csis = <DVFS_CSIS_L5>;
			secure_front_mif = <DVFS_MIF_L6>;
			secure_front_int = <DVFS_INT_L3>;
			secure_front_hpg = <1>;

			pip_preview_int_cam = <DVFS_INT_CAM_L3>;
			pip_preview_cam = <DVFS_CAM_L2>;
			pip_preview_csis = <DVFS_CSIS_L2>;
			pip_preview_mif = <DVFS_MIF_L1>;
			pip_preview_int = <DVFS_INT_L3>;
			pip_preview_hpg = <1>;

			pip_capture_int_cam = <DVFS_INT_CAM_L3>;
			pip_capture_cam = <DVFS_CAM_L2>;
			pip_capture_csis = <DVFS_CSIS_L2>;
			pip_capture_mif = <DVFS_MIF_L1>;
			pip_capture_int = <DVFS_INT_L0>;
			pip_capture_hpg = <1>;

			pip_video_int_cam = <DVFS_INT_CAM_L3>;
			pip_video_cam = <DVFS_CAM_L2>;
			pip_video_csis = <DVFS_CSIS_L2>;
			pip_video_mif = <DVFS_MIF_L1>;
			pip_video_int = <DVFS_INT_L3>;
			pip_video_hpg = <1>;

			pip_video_capture_int_cam = <DVFS_INT_CAM_L3>;
			pip_video_capture_cam = <DVFS_CAM_L1>;
			pip_video_capture_csis = <DVFS_CSIS_L1>;
			pip_video_capture_mif = <DVFS_MIF_L1>;
			pip_video_capture_int = <DVFS_INT_L0>;
			pip_video_capture_hpg = <1>;

			preview_high_speed_fps_int_cam = <DVFS_INT_CAM_L4>;
			preview_high_speed_fps_cam = <DVFS_CAM_L3>;		/* VOTF */
			preview_high_speed_fps_csis = <DVFS_CSIS_L3>;	/* VOTF */
			preview_high_speed_fps_mif = <DVFS_MIF_L4>;
			preview_high_speed_fps_int = <DVFS_INT_L3>;
			preview_high_speed_fps_hpg = <1>;

			video_high_speed_60fps_int_cam = <DVFS_INT_CAM_L5>;
			video_high_speed_60fps_cam = <DVFS_CAM_L3>;		/* VOTF */
			video_high_speed_60fps_csis = <DVFS_CSIS_L3>;	/* VOTF */
			video_high_speed_60fps_mif = <DVFS_MIF_L6>;
			video_high_speed_60fps_int = <DVFS_INT_L3>;
			video_high_speed_60fps_hpg = <1>;

			video_high_speed_120fps_int_cam = <DVFS_INT_CAM_L5>;
			video_high_speed_120fps_cam = <DVFS_CAM_L3>;	/* VOTF */
			video_high_speed_120fps_csis = <DVFS_CSIS_L3>;	/* VOTF */
			video_high_speed_120fps_mif = <DVFS_MIF_L4>;
			video_high_speed_120fps_int = <DVFS_INT_L3>;
			video_high_speed_120fps_hpg = <1>;

			video_high_speed_240fps_int_cam = <DVFS_INT_CAM_L4>;
			video_high_speed_240fps_cam = <DVFS_CAM_L3>;	/* VOTF */
			video_high_speed_240fps_csis = <DVFS_CSIS_L3>;	/* VOTF */
			video_high_speed_240fps_mif = <DVFS_MIF_L4>;
			video_high_speed_240fps_int = <DVFS_INT_L2>;
			video_high_speed_240fps_hpg = <1>;

			video_high_speed_480fps_int_cam = <DVFS_INT_CAM_L4>;
			video_high_speed_480fps_cam = <DVFS_CAM_L3>;	/* VOTF */
			video_high_speed_480fps_csis = <DVFS_CSIS_L3>;	/* VOTF */
			video_high_speed_480fps_mif = <DVFS_MIF_L4>;
			video_high_speed_480fps_int = <DVFS_INT_L1>;
			video_high_speed_480fps_hpg = <1>;

			video_high_speed_960fps_int_cam = <DVFS_INT_CAM_L4>;
			video_high_speed_960fps_cam = <DVFS_CAM_L3>;	/* VOTF */
			video_high_speed_960fps_csis = <DVFS_CSIS_L3>;	/* VOTF */
			video_high_speed_960fps_mif = <DVFS_MIF_L4>;
			video_high_speed_960fps_int = <DVFS_INT_L1>;
			video_high_speed_960fps_hpg = <1>;

			video_high_speed_dualfps_int_cam = <DVFS_INT_CAM_L4>;
			video_high_speed_dualfps_cam = <DVFS_CAM_L3>;	/* VOTF */
			video_high_speed_dualfps_csis = <DVFS_CSIS_L3>;	/* VOTF */
			video_high_speed_dualfps_mif = <DVFS_MIF_L4>;
			video_high_speed_dualfps_int = <DVFS_INT_L1>;
			video_high_speed_dualfps_hpg = <6>;

			video_high_speed_60fps_capture_int_cam = <DVFS_INT_CAM_L3>;
			video_high_speed_60fps_capture_cam = <DVFS_CAM_L3>;	/* VOTF */
			video_high_speed_60fps_capture_csis = <DVFS_CSIS_L3>;	/* VOTF */
			video_high_speed_60fps_capture_mif = <DVFS_MIF_L1>;
			video_high_speed_60fps_capture_int = <DVFS_INT_L0>;
			video_high_speed_60fps_capture_hpg = <1>;

			ext_rear_int_cam = <DVFS_INT_CAM_L5>;
			ext_rear_cam = <DVFS_CAM_L5>;
			ext_rear_csis = <DVFS_CSIS_L5>;
			ext_rear_mif = <DVFS_MIF_L8>;
			ext_rear_int = <DVFS_INT_L3>;
			ext_rear_hpg = <1>;

			ext_secure_int_cam = <DVFS_INT_CAM_L5>;
			ext_secure_cam = <DVFS_CAM_L5>;
			ext_secure_csis = <DVFS_CSIS_L5>;
			ext_secure_mif = <DVFS_MIF_L8>;
			ext_secure_int = <DVFS_INT_L3>;
			ext_secure_hpg = <1>;

			max_int_cam = <DVFS_INT_CAM_L0>;
			max_cam = <DVFS_CAM_L0>;
			max_csis = <DVFS_CSIS_L0>;
			max_mif = <DVFS_MIF_L0>;
			max_int = <DVFS_INT_L0>;
			max_hpg = <1>;
		};
	};
};
